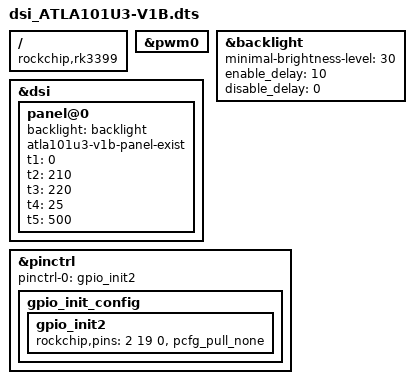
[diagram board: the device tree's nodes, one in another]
/dts-v1/;
/plugin/;
/ {
	compatible = "rockchip,rk3399";

	fragment@0 {
		target = <&pwm0>;
		__overlay__ {
			status = "okay";
		};
	};
	fragment@1 {
		target = <&backlight>;
		__overlay__ {
			status = "okay";
			minimal-brightness-level = <30>;
            enable_delay = <10>;
            disable_delay = <0>;
		};
	};
	fragment@2 {
		target = <&dsi>;
		__overlay__ {
			status = "okay";
			panel@0 {
				backlight = <&backlight>;
                atla101u3-v1b-panel-exist;

                t1=<0>;//VCC on to start DSi signal
				t2=<210>;//DSI signal(start) to turn Backlihgt on
				t3=<220>;//Backlihgt(off) to stop DSI signal
				t4=<25>;//DSI signal to turn VCC off
				t5=<500>;//VCC off to turn VCC on
			};
		};
	};
	fragment@3 {
		target = <&pinctrl>;
		__overlay__ {
			pinctrl-0 = <&gpio_init2>;
			gpio_init_config {
				gpio_init2: gpio_init2 {
					rockchip,pins =
						<2 19 0 &pcfg_pull_none>;
				};
			};
		};
	};
};
